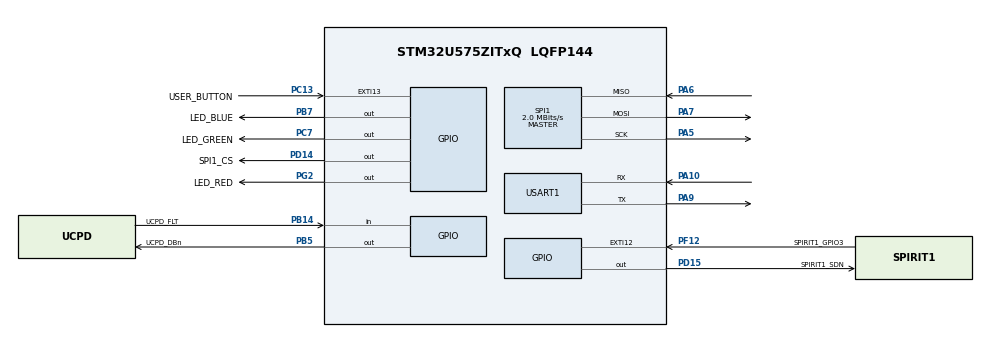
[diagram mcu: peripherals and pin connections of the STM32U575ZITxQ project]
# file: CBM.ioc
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CORTEX_M33_NS.userName=CORTEX_M33
Mcu.Family=STM32U5
Mcu.Name=STM32U575ZITxQ
Mcu.Package=LQFP144
NVIC.EXTI12_IRQn=true\:0\:0\:false\:false\:true\:true\:true
NVIC.PriorityGroup=NVIC_PRIORITYGROUP_3
NVIC.TIM17_IRQn=true\:7\:0\:false\:false\:true\:false\:true
NVIC.TimeBase=TIM17_IRQn
NVIC.TimeBaseIP=TIM17
PA10.Mode=Asynchronous
PA10.Signal=USART1_RX
PA11.Signal=USB_OTG_FS_DM
PA12.Signal=USB_OTG_FS_DP
PA13\ (JTMS/SWDIO).Signal=DEBUG_JTMS-SWDIO
PA14\ (JTCK/SWCLK).Signal=DEBUG_JTCK-SWCLK
PA15\ (JTDI).Signal=UCPD1_CC1
PA5.Mode=Full_Duplex_Master
PA5.Signal=SPI1_SCK
PA6.Mode=Full_Duplex_Master
PA6.Signal=SPI1_MISO
PA7.Mode=Full_Duplex_Master
PA7.Signal=SPI1_MOSI
PA9.Mode=Asynchronous
PA9.Signal=USART1_TX
PB14.GPIO_Label=UCPD_FLT
PB14.Signal=GPIO_Input
PB15.Signal=UCPD1_CC2
PB3\ (JTDO/TRACESWO).Signal=DEBUG_JTDO-SWO
PB5.GPIO_Label=UCPD_DBn
PB5.Signal=GPIO_Output
PB7.GPIO_Label=LED_BLUE
PB7.Signal=GPIO_Output
PC13.GPIO_Label=USER_BUTTON
PC13.Signal=GPXTI13
PC14-OSC32_IN\ (PC14).Signal=RCC_OSC32_IN
PC15-OSC32_OUT\ (PC15).Signal=RCC_OSC32_OUT
PC2.GPIO_Label=VBUS_SENSE
PC2.Signal=ADC1_IN3
PC7.GPIO_Label=LED_GREEN
PC7.Signal=GPIO_Output
PD14.GPIO_Label=SPI1_CS
PD14.Signal=GPIO_Output
PD15.GPIO_Label=SPIRIT1_SDN
PD15.Signal=GPIO_Output
PF12.GPIO_Label=SPIRIT1_GPIO3
PF12.GPIO_ModeDefaultEXTI=GPIO_MODE_IT_FALLING
PF12.Signal=GPXTI12
PG2.GPIO_Label=LED_RED
PG2.Signal=GPIO_Output
ProjectManager.HeapSize=0x200
ProjectManager.StackSize=0x400
ProjectManager.TargetToolchain=STM32CubeIDE
RCC.DACCLockSelectionVirtual=RCC_DAC1CLKSOURCE_LSI
RCC.DACCLockSelectionVirtualString=RCC_DAC1CLKSOURCE_LSI
RCC.EPOD_VALUE=4000000
RCC.HSE_VALUE=16000000
RCC.HSI48_VALUE=48000000
RCC.HSI_VALUE=16000000
RCC.LSE_VALUE=32768
RCC.LSIDIV_VALUE=32000
RCC.MSI_VALUE=4000000
RCC.USBFreq_Value=48000000
RCC.VCOOutputFreq_Value=516000000
SPI1.CalculateBaudRate=2.0 MBits/s
SPI1.Direction=SPI_DIRECTION_2LINES
SPI1.Mode=SPI_MODE_MASTER
SPI1.VirtualType=VM_MASTER
USART1.VirtualMode-Asynchronous=VM_ASYNC
VP_PWR_VS_DBSignals.Mode=DisableDeadBatterySignals
VP_PWR_VS_SECSignals.Mode=Security/Privilege
VP_SYS_VS_tim17.Mode=TIM17
board=NUCLEO-U575ZI-Q

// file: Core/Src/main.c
/* USER CODE BEGIN Header */
/**
  ******************************************************************************
  * @file           : main.c
  * @brief          : Main program body
  ******************************************************************************
  * @attention
  *
  * Copyright (c) 2022 STMicroelectronics.
  * All rights reserved.
  *
  * This software is licensed under terms that can be found in the LICENSE file
  * in the root directory of this software component.
  * If no LICENSE file comes with this software, it is provided AS-IS.
  *
  ******************************************************************************
  */
/* USER CODE END Header */
#include "main.h"

/* USER CODE BEGIN Includes */
#include "SPIRIT_Config.h"
/* USER CODE END Includes */

SPI_HandleTypeDef hspi1;

UART_HandleTypeDef huart1;

void SystemClock_Config(void);
static void MX_GPIO_Init(void);
static void MX_USART1_UART_Init(void);
static void MX_SPI1_Init(void);

int main(void)
{

  /* MCU Configuration--------------------------------------------------------*/

  /* Reset of all peripherals, Initializes the Flash interface and the Systick. */
  HAL_Init();
  HAL_PWREx_EnableVddIO2();

  /* Configure the system clock */
  SystemClock_Config();

  /* Initialize all configured peripherals */
  MX_GPIO_Init();
  MX_USART1_UART_Init();
  MX_SPI1_Init();
  /* USER CODE BEGIN 2 */
  SpiritSpiInit();
  /* USER CODE END 2 */

  /* Infinite loop */
  /* USER CODE BEGIN WHILE */
  char test[] = "dit is een test\r\n";
  while (1)
  {
	  HAL_GPIO_TogglePin(LED_RED_GPIO_Port, LED_RED_Pin);
	  	HAL_GPIO_TogglePin(LED_GREEN_GPIO_Port, LED_GREEN_Pin);
	  	HAL_GPIO_TogglePin(GPIOB, LED_BLUE_Pin);
	  	HAL_Delay(500);
	  	HAL_UART_Transmit(&huart1, test, sizeof(test), 100);
    /* USER CODE END WHILE */

  }
}

void SystemClock_Config(void)
{
  RCC_OscInitTypeDef RCC_OscInitStruct = {0};
  RCC_ClkInitTypeDef RCC_ClkInitStruct = {0};

  /** Configure the main internal regulator output voltage
  */
  if (HAL_PWREx_ControlVoltageScaling(PWR_REGULATOR_VOLTAGE_SCALE4) != HAL_OK)
  {
    Error_Handler();
  }
  /** Initializes the CPU, AHB and APB busses clocks
  */
  RCC_OscInitStruct.OscillatorType = RCC_OSCILLATORTYPE_MSI;
  RCC_OscInitStruct.MSIState = RCC_MSI_ON;
  RCC_OscInitStruct.MSICalibrationValue = RCC_MSICALIBRATION_DEFAULT;
  RCC_OscInitStruct.MSIClockRange = RCC_MSIRANGE_4;
  RCC_OscInitStruct.PLL.PLLState = RCC_PLL_NONE;
  if (HAL_RCC_OscConfig(&RCC_OscInitStruct) != HAL_OK)
  {
    Error_Handler();
  }
  /** Initializes the CPU, AHB and APB busses clocks
  */
  RCC_ClkInitStruct.ClockType = RCC_CLOCKTYPE_HCLK|RCC_CLOCKTYPE_SYSCLK
                              |RCC_CLOCKTYPE_PCLK1|RCC_CLOCKTYPE_PCLK2
                              |RCC_CLOCKTYPE_PCLK3;
  RCC_ClkInitStruct.SYSCLKSource = RCC_SYSCLKSOURCE_MSI;
  RCC_ClkInitStruct.AHBCLKDivider = RCC_SYSCLK_DIV1;
  RCC_ClkInitStruct.APB1CLKDivider = RCC_HCLK_DIV1;
  RCC_ClkInitStruct.APB2CLKDivider = RCC_HCLK_DIV1;
  RCC_ClkInitStruct.APB3CLKDivider = RCC_HCLK_DIV1;

  if (HAL_RCC_ClockConfig(&RCC_ClkInitStruct, FLASH_LATENCY_0) != HAL_OK)
  {
    Error_Handler();
  }
  __HAL_RCC_PWR_CLK_DISABLE();
}

static void MX_SPI1_Init(void)
{

  SPI_AutonomousModeConfTypeDef HAL_SPI_AutonomousMode_Cfg_Struct = {0};

  /* SPI1 parameter configuration*/
  hspi1.Instance = SPI1;
  hspi1.Init.Mode = SPI_MODE_MASTER;
  hspi1.Init.Direction = SPI_DIRECTION_2LINES;
  hspi1.Init.DataSize = SPI_DATASIZE_4BIT;
  hspi1.Init.CLKPolarity = SPI_POLARITY_LOW;
  hspi1.Init.CLKPhase = SPI_PHASE_1EDGE;
  hspi1.Init.NSS = SPI_NSS_SOFT;
  hspi1.Init.BaudRatePrescaler = SPI_BAUDRATEPRESCALER_2;
  hspi1.Init.FirstBit = SPI_FIRSTBIT_MSB;
  hspi1.Init.TIMode = SPI_TIMODE_DISABLE;
  hspi1.Init.CRCCalculation = SPI_CRCCALCULATION_DISABLE;
  hspi1.Init.CRCPolynomial = 0x7;
  hspi1.Init.NSSPMode = SPI_NSS_PULSE_ENABLE;
  hspi1.Init.NSSPolarity = SPI_NSS_POLARITY_LOW;
  hspi1.Init.FifoThreshold = SPI_FIFO_THRESHOLD_01DATA;
  hspi1.Init.TxCRCInitializationPattern = SPI_CRC_INITIALIZATION_ALL_ZERO_PATTERN;
  hspi1.Init.RxCRCInitializationPattern = SPI_CRC_INITIALIZATION_ALL_ZERO_PATTERN;
  hspi1.Init.MasterSSIdleness = SPI_MASTER_SS_IDLENESS_00CYCLE;
  hspi1.Init.MasterInterDataIdleness = SPI_MASTER_INTERDATA_IDLENESS_00CYCLE;
  hspi1.Init.MasterReceiverAutoSusp = SPI_MASTER_RX_AUTOSUSP_DISABLE;
  hspi1.Init.MasterKeepIOState = SPI_MASTER_KEEP_IO_STATE_DISABLE;
  hspi1.Init.IOSwap = SPI_IO_SWAP_DISABLE;
  hspi1.Init.ReadyMasterManagement = SPI_RDY_MASTER_MANAGEMENT_INTERNALLY;
  hspi1.Init.ReadyPolarity = SPI_RDY_POLARITY_HIGH;
  if (HAL_SPI_Init(&hspi1) != HAL_OK)
  {
    Error_Handler();
  }
  HAL_SPI_AutonomousMode_Cfg_Struct.TriggerState = SPI_AUTO_MODE_DISABLE;
  HAL_SPI_AutonomousMode_Cfg_Struct.TriggerSelection = SPI_GRP1_GPDMA_CH0_TCF_TRG;
  HAL_SPI_AutonomousMode_Cfg_Struct.TriggerPolarity = SPI_TRIG_POLARITY_RISING;
  if (HAL_SPIEx_SetConfigAutonomousMode(&hspi1, &HAL_SPI_AutonomousMode_Cfg_Struct) != HAL_OK)
  {
    Error_Handler();
  }

}

static void MX_USART1_UART_Init(void)
{

  huart1.Instance = USART1;
  huart1.Init.BaudRate = 115200;
  huart1.Init.WordLength = UART_WORDLENGTH_8B;
  huart1.Init.StopBits = UART_STOPBITS_1;
  huart1.Init.Parity = UART_PARITY_NONE;
  huart1.Init.Mode = UART_MODE_TX_RX;
  huart1.Init.HwFlowCtl = UART_HWCONTROL_NONE;
  huart1.Init.OverSampling = UART_OVERSAMPLING_16;
  huart1.Init.OneBitSampling = UART_ONE_BIT_SAMPLE_DISABLE;
  huart1.Init.ClockPrescaler = UART_PRESCALER_DIV1;
  huart1.AdvancedInit.AdvFeatureInit = UART_ADVFEATURE_NO_INIT;
  if (HAL_UART_Init(&huart1) != HAL_OK)
  {
    Error_Handler();
  }
  if (HAL_UARTEx_SetTxFifoThreshold(&huart1, UART_TXFIFO_THRESHOLD_1_8) != HAL_OK)
  {
    Error_Handler();
  }
  if (HAL_UARTEx_SetRxFifoThreshold(&huart1, UART_RXFIFO_THRESHOLD_1_8) != HAL_OK)
  {
    Error_Handler();
  }
  if (HAL_UARTEx_DisableFifoMode(&huart1) != HAL_OK)
  {
    Error_Handler();
  }

}

static void MX_GPIO_Init(void)
{
  GPIO_InitTypeDef GPIO_InitStruct = {0};

  /* GPIO Ports Clock Enable */
  __HAL_RCC_GPIOC_CLK_ENABLE();
  __HAL_RCC_GPIOA_CLK_ENABLE();
  __HAL_RCC_GPIOF_CLK_ENABLE();
  __HAL_RCC_GPIOB_CLK_ENABLE();
  __HAL_RCC_GPIOD_CLK_ENABLE();
  __HAL_RCC_GPIOG_CLK_ENABLE();

  /*Configure GPIO pin Output Level */
  HAL_GPIO_WritePin(GPIOD, SPI1_CS_Pin|SPIRIT1_SDN_Pin, GPIO_PIN_RESET);

  /*Configure GPIO pin Output Level */
  HAL_GPIO_WritePin(LED_RED_GPIO_Port, LED_RED_Pin, GPIO_PIN_RESET);

  /*Configure GPIO pin Output Level */
  HAL_GPIO_WritePin(LED_GREEN_GPIO_Port, LED_GREEN_Pin, GPIO_PIN_RESET);

  /*Configure GPIO pin Output Level */
  HAL_GPIO_WritePin(GPIOB, UCPD_DBn_Pin|LED_BLUE_Pin, GPIO_PIN_RESET);

  /*Configure GPIO pin : USER_BUTTON_Pin */
  GPIO_InitStruct.Pin = USER_BUTTON_Pin;
  GPIO_InitStruct.Mode = GPIO_MODE_IT_RISING;
  GPIO_InitStruct.Pull = GPIO_NOPULL;
  HAL_GPIO_Init(USER_BUTTON_GPIO_Port, &GPIO_InitStruct);

  /*Configure GPIO pin : VBUS_SENSE_Pin */
  GPIO_InitStruct.Pin = VBUS_SENSE_Pin;
  GPIO_InitStruct.Mode = GPIO_MODE_ANALOG;
  GPIO_InitStruct.Pull = GPIO_NOPULL;
  HAL_GPIO_Init(VBUS_SENSE_GPIO_Port, &GPIO_InitStruct);

  /*Configure GPIO pin : SPIRIT1_GPIO3_Pin */
  GPIO_InitStruct.Pin = SPIRIT1_GPIO3_Pin;
  GPIO_InitStruct.Mode = GPIO_MODE_IT_FALLING;
  GPIO_InitStruct.Pull = GPIO_NOPULL;
  HAL_GPIO_Init(SPIRIT1_GPIO3_GPIO_Port, &GPIO_InitStruct);

  /*Configure GPIO pin : UCPD_FLT_Pin */
  GPIO_InitStruct.Pin = UCPD_FLT_Pin;
  GPIO_InitStruct.Mode = GPIO_MODE_INPUT;
  GPIO_InitStruct.Pull = GPIO_NOPULL;
  HAL_GPIO_Init(UCPD_FLT_GPIO_Port, &GPIO_InitStruct);

  /*Configure GPIO pin : PB15 */
  GPIO_InitStruct.Pin = GPIO_PIN_15;
  GPIO_InitStruct.Mode = GPIO_MODE_ANALOG;
  GPIO_InitStruct.Pull = GPIO_NOPULL;
  HAL_GPIO_Init(GPIOB, &GPIO_InitStruct);

  /*Configure GPIO pins : SPI1_CS_Pin SPIRIT1_SDN_Pin */
  GPIO_InitStruct.Pin = SPI1_CS_Pin|SPIRIT1_SDN_Pin;
  GPIO_InitStruct.Mode = GPIO_MODE_OUTPUT_PP;
  GPIO_InitStruct.Pull = GPIO_NOPULL;
  GPIO_InitStruct.Speed = GPIO_SPEED_FREQ_LOW;
  HAL_GPIO_Init(GPIOD, &GPIO_InitStruct);

  /*Configure GPIO pin : LED_RED_Pin */
  GPIO_InitStruct.Pin = LED_RED_Pin;
  GPIO_InitStruct.Mode = GPIO_MODE_OUTPUT_PP;
  GPIO_InitStruct.Pull = GPIO_NOPULL;
  GPIO_InitStruct.Speed = GPIO_SPEED_FREQ_LOW;
  HAL_GPIO_Init(LED_RED_GPIO_Port, &GPIO_InitStruct);

  /*Configure GPIO pin : LED_GREEN_Pin */
  GPIO_InitStruct.Pin = LED_GREEN_Pin;
  GPIO_InitStruct.Mode = GPIO_MODE_OUTPUT_PP;
  GPIO_InitStruct.Pull = GPIO_NOPULL;
  GPIO_InitStruct.Speed = GPIO_SPEED_FREQ_LOW;
  HAL_GPIO_Init(LED_GREEN_GPIO_Port, &GPIO_InitStruct);

  /*Configure GPIO pins : PA11 PA12 */
  GPIO_InitStruct.Pin = GPIO_PIN_11|GPIO_PIN_12;
  GPIO_InitStruct.Mode = GPIO_MODE_AF_PP;
  GPIO_InitStruct.Pull = GPIO_NOPULL;
  GPIO_InitStruct.Speed = GPIO_SPEED_FREQ_LOW;
  GPIO_InitStruct.Alternate = GPIO_AF10_USB;
  HAL_GPIO_Init(GPIOA, &GPIO_InitStruct);

  /*Configure GPIO pin : PA15 */
  GPIO_InitStruct.Pin = GPIO_PIN_15;
  GPIO_InitStruct.Mode = GPIO_MODE_ANALOG;
  GPIO_InitStruct.Pull = GPIO_NOPULL;
  HAL_GPIO_Init(GPIOA, &GPIO_InitStruct);

  /*Configure GPIO pins : UCPD_DBn_Pin LED_BLUE_Pin */
  GPIO_InitStruct.Pin = UCPD_DBn_Pin|LED_BLUE_Pin;
  GPIO_InitStruct.Mode = GPIO_MODE_OUTPUT_PP;
  GPIO_InitStruct.Pull = GPIO_NOPULL;
  GPIO_InitStruct.Speed = GPIO_SPEED_FREQ_LOW;
  HAL_GPIO_Init(GPIOB, &GPIO_InitStruct);

  /* EXTI interrupt init*/
  HAL_NVIC_SetPriority(EXTI12_IRQn, 0, 0);
  HAL_NVIC_EnableIRQ(EXTI12_IRQn);

}

void HAL_TIM_PeriodElapsedCallback(TIM_HandleTypeDef *htim)
{
  if (htim->Instance == TIM17) {
    HAL_IncTick();
  }
}

void Error_Handler(void)
{
  __disable_irq();
  while (1)
  {
  }
}
